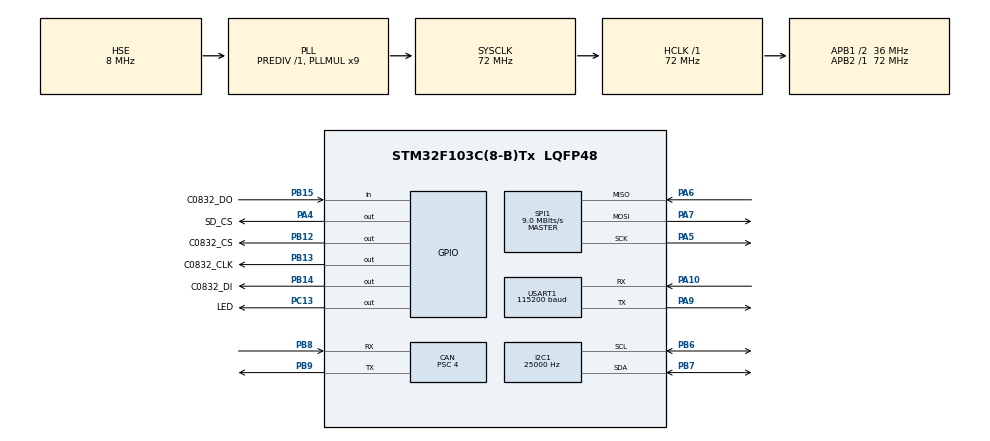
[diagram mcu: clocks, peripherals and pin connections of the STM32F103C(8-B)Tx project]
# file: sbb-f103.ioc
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CAN.BS1=CAN_BS1_6TQ
CAN.BS2=CAN_BS2_2TQ
CAN.CalculateBaudRate=1000000
CAN.CalculateTimeQuantum=111.11111111111111
CAN.Prescaler=4
CAN.SJW=CAN_SJW_1TQ
FREERTOS.INCLUDE_uxTaskGetStackHighWaterMark=1
FREERTOS.MEMORY_ALLOCATION=1
FREERTOS.Tasks01=defaultTask,0,128,StartDefaultTask,Default,NULL,Static,defaultTaskBuffer,defaultTaskControlBlock
FREERTOS.configCHECK_FOR_STACK_OVERFLOW=2
FREERTOS.copyHeapFile=0
I2C1.ClockSpeed=25000
Mcu.Family=STM32F1
Mcu.Name=STM32F103C(8-B)Tx
Mcu.Package=LQFP48
NVIC.PriorityGroup=NVIC_PRIORITYGROUP_4
NVIC.TIM3_IRQn=true\:15\:0\:false\:false\:true\:false\:false\:true\:true
NVIC.TimeBase=TIM3_IRQn
NVIC.TimeBaseIP=TIM3
PA10.Mode=Asynchronous
PA10.Signal=USART1_RX
PA13.Mode=Serial_Wire
PA13.Signal=SYS_JTMS-SWDIO
PA14.Mode=Serial_Wire
PA14.Signal=SYS_JTCK-SWCLK
PA4.GPIO_Label=SD_CS
PA4.Signal=GPIO_Output
PA5.Mode=Full_Duplex_Master
PA5.Signal=SPI1_SCK
PA6.Mode=Full_Duplex_Master
PA6.Signal=SPI1_MISO
PA7.Mode=Full_Duplex_Master
PA7.Signal=SPI1_MOSI
PA9.Mode=Asynchronous
PA9.Signal=USART1_TX
PB12.GPIO_Label=C0832_CS
PB12.PinState=GPIO_PIN_SET
PB12.Signal=GPIO_Output
PB13.GPIO_Label=C0832_CLK
PB13.PinState=GPIO_PIN_RESET
PB13.Signal=GPIO_Output
PB14.GPIO_Label=C0832_DI
PB14.PinState=GPIO_PIN_RESET
PB14.Signal=GPIO_Output
PB15.GPIO_Label=C0832_DO
PB15.GPIO_PuPd=GPIO_NOPULL
PB15.Signal=GPIO_Input
PB6.Mode=I2C
PB6.Signal=I2C1_SCL
PB7.Mode=I2C
PB7.Signal=I2C1_SDA
PB8.Mode=CAN_Activate
PB8.Signal=CAN_RX
PB9.Mode=CAN_Activate
PB9.Signal=CAN_TX
PC13-TAMPER-RTC.GPIO_Label=LED
PC13-TAMPER-RTC.PinState=GPIO_PIN_SET
PC13-TAMPER-RTC.Signal=GPIO_Output
PD0-OSC_IN.Mode=HSE-External-Oscillator
PD0-OSC_IN.Signal=RCC_OSC_IN
PD1-OSC_OUT.Mode=HSE-External-Oscillator
PD1-OSC_OUT.Signal=RCC_OSC_OUT
ProjectManager.HeapSize=0x200
ProjectManager.StackSize=0x400
ProjectManager.TargetToolchain=Makefile
RCC.AHBFreq_Value=72000000
RCC.APB1CLKDivider=RCC_HCLK_DIV2
RCC.APB1Freq_Value=36000000
RCC.APB1TimFreq_Value=72000000
RCC.APB2Freq_Value=72000000
RCC.APB2TimFreq_Value=72000000
RCC.HCLKFreq_Value=72000000
RCC.PLLMUL=RCC_PLL_MUL9
RCC.PLLSourceVirtual=RCC_PLLSOURCE_HSE
RCC.SYSCLKFreq_VALUE=72000000
RCC.SYSCLKSource=RCC_SYSCLKSOURCE_PLLCLK
RCC.USBFreq_Value=72000000
SPI1.BaudRatePrescaler=SPI_BAUDRATEPRESCALER_8
SPI1.CalculateBaudRate=9.0 MBits/s
SPI1.Direction=SPI_DIRECTION_2LINES
SPI1.Mode=SPI_MODE_MASTER
SPI1.VirtualType=VM_MASTER
USART1.BaudRate=115200
USART1.Mode=MODE_TX_RX
USART1.Parity=PARITY_NONE
USART1.StopBits=STOPBITS_1
USART1.VirtualMode=VM_ASYNC
USART1.WordLength=WORDLENGTH_8B
VP_FREERTOS_VS_CMSIS_V1.Mode=CMSIS_V1
VP_SYS_VS_tim3.Mode=TIM3
board=custom

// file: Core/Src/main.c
/* USER CODE BEGIN Header */
/**
  ******************************************************************************
  * @file           : main.c
  * @brief          : Main program body
  ******************************************************************************
  * @attention
  *
  * Copyright (c) 2026 STMicroelectronics.
  * All rights reserved.
  *
  * This software is licensed under terms that can be found in the LICENSE file
  * in the root directory of this software component.
  * If no LICENSE file comes with this software, it is provided AS-IS.
  *
  ******************************************************************************
  */
/* USER CODE END Header */
#include "main.h"
#include "cmsis_os.h"

/* USER CODE BEGIN Includes */
#include "app_main.h"      /* 应用层入口（App/app/app_main.c）*/
/* USER CODE END Includes */

CAN_HandleTypeDef hcan;

I2C_HandleTypeDef hi2c1;

SPI_HandleTypeDef hspi1;

UART_HandleTypeDef huart1;

osThreadId defaultTaskHandle;
uint32_t defaultTaskBuffer[ 128 ];
osStaticThreadDef_t defaultTaskControlBlock;

void SystemClock_Config(void);
static void MX_GPIO_Init(void);
static void MX_CAN_Init(void);
static void MX_I2C1_Init(void);
static void MX_SPI1_Init(void);
static void MX_USART1_UART_Init(void);
void StartDefaultTask(void const * argument);

int main(void)
{

  /* MCU Configuration--------------------------------------------------------*/

  /* Reset of all peripherals, Initializes the Flash interface and the Systick. */
  HAL_Init();

  /* Configure the system clock */
  SystemClock_Config();

  /* Initialize all configured peripherals */
  MX_GPIO_Init();
  MX_CAN_Init();
  MX_I2C1_Init();
  MX_SPI1_Init();
  MX_USART1_UART_Init();

  /* Create the thread(s) */
  /* definition and creation of defaultTask */
  osThreadStaticDef(defaultTask, StartDefaultTask, osPriorityNormal, 0, 128, defaultTaskBuffer, &defaultTaskControlBlock);
  defaultTaskHandle = osThreadCreate(osThread(defaultTask), NULL);

  /* USER CODE BEGIN RTOS_THREADS */
  /* 建应用任务（全静态分配，实现见 App/app/app_main.c）*/
  app_start();
  /* USER CODE END RTOS_THREADS */

  /* Start scheduler */
  osKernelStart();

  /* We should never get here as control is now taken by the scheduler */

  /* Infinite loop */
  while (1)
  {

  }
}

void SystemClock_Config(void)
{
  RCC_OscInitTypeDef RCC_OscInitStruct = {0};
  RCC_ClkInitTypeDef RCC_ClkInitStruct = {0};

  /** Initializes the RCC Oscillators according to the specified parameters
  * in the RCC_OscInitTypeDef structure.
  */
  RCC_OscInitStruct.OscillatorType = RCC_OSCILLATORTYPE_HSE;
  /* ★ [AI-TEMP-FIX] 由 RCC_HSE_BYPASS 改为 RCC_HSE_ON。
   *   蓝 pill 板载 8 MHz **无源晶振**，而原 .ioc 把 HSE 写成了
   *   "HSE-External-Clock-Source"（= bypass，期待外部时钟信号）→ HSERDY 永不置位
   *   → HAL_RCC_OscConfig 返回错误 → Error_Handler() 死循环，应用从未启动
   *   （真机证据：RCC_CR=0x00054783 即 HSEBYP=1/HSERDY=0，RCC_CFGR=0，xTickCount=0）。
   *   .ioc 已同步改为 HSE-External-Oscillator；**你在 CubeMX 里重新 GENERATE CODE
   *   后本行会被正确覆盖，届时可删除此注释**。留档见 docs/CUBEMX-TODO.md A0。 */
  RCC_OscInitStruct.HSEState = RCC_HSE_ON;
  RCC_OscInitStruct.HSEPredivValue = RCC_HSE_PREDIV_DIV1;
  RCC_OscInitStruct.HSIState = RCC_HSI_ON;
  RCC_OscInitStruct.PLL.PLLState = RCC_PLL_ON;
  RCC_OscInitStruct.PLL.PLLSource = RCC_PLLSOURCE_HSE;
  RCC_OscInitStruct.PLL.PLLMUL = RCC_PLL_MUL9;
  if (HAL_RCC_OscConfig(&RCC_OscInitStruct) != HAL_OK)
  {
    Error_Handler();
  }

  /** Initializes the CPU, AHB and APB buses clocks
  */
  RCC_ClkInitStruct.ClockType = RCC_CLOCKTYPE_HCLK|RCC_CLOCKTYPE_SYSCLK
                              |RCC_CLOCKTYPE_PCLK1|RCC_CLOCKTYPE_PCLK2;
  RCC_ClkInitStruct.SYSCLKSource = RCC_SYSCLKSOURCE_PLLCLK;
  RCC_ClkInitStruct.AHBCLKDivider = RCC_SYSCLK_DIV1;
  RCC_ClkInitStruct.APB1CLKDivider = RCC_HCLK_DIV2;
  RCC_ClkInitStruct.APB2CLKDivider = RCC_HCLK_DIV1;

  if (HAL_RCC_ClockConfig(&RCC_ClkInitStruct, FLASH_LATENCY_2) != HAL_OK)
  {
    Error_Handler();
  }
}

static void MX_CAN_Init(void)
{

  hcan.Instance = CAN1;
  hcan.Init.Prescaler = 4;
  hcan.Init.Mode = CAN_MODE_NORMAL;
  hcan.Init.SyncJumpWidth = CAN_SJW_1TQ;
  hcan.Init.TimeSeg1 = CAN_BS1_6TQ;
  hcan.Init.TimeSeg2 = CAN_BS2_2TQ;
  hcan.Init.TimeTriggeredMode = DISABLE;
  hcan.Init.AutoBusOff = DISABLE;
  hcan.Init.AutoWakeUp = DISABLE;
  hcan.Init.AutoRetransmission = DISABLE;
  hcan.Init.ReceiveFifoLocked = DISABLE;
  hcan.Init.TransmitFifoPriority = DISABLE;
  if (HAL_CAN_Init(&hcan) != HAL_OK)
  {
    Error_Handler();
  }

}

static void MX_I2C1_Init(void)
{

  hi2c1.Instance = I2C1;
  /* ★ 25kHz 而不是 50kHz/100kHz —— 真机实测结论，别轻易调高：
   *   本板 OLED 走线为长杜邦线，总线上升沿 t_r 实测约 1.3~2.1µs（模块自带约 10kΩ 上拉偏弱）。
   *   在 50kHz（周期 20µs）下外设会误采样 SCL，出现"面板半混乱 → 持续时钟拉伸"，
   *   单个 129 字节事务从理论 23ms 恶化到 330ms（刷屏 5.3s，实测）。
   *   25kHz 下实测单次刷屏 482ms（理论 372ms，1.3 倍，可接受）。
   *   根治办法是硬件：SCL/SDA 各并 4.7kΩ 到 3V3，之后才谈提速。
   *   ⚠ 改回高速度前，必须先复核 bsp_i2c.c 里的 BSP_I2C_TIMEOUT_MS 余量。 */
  hi2c1.Init.ClockSpeed = 25000;
  hi2c1.Init.DutyCycle = I2C_DUTYCYCLE_2;
  hi2c1.Init.OwnAddress1 = 0;
  hi2c1.Init.AddressingMode = I2C_ADDRESSINGMODE_7BIT;
  hi2c1.Init.DualAddressMode = I2C_DUALADDRESS_DISABLE;
  hi2c1.Init.OwnAddress2 = 0;
  hi2c1.Init.GeneralCallMode = I2C_GENERALCALL_DISABLE;
  hi2c1.Init.NoStretchMode = I2C_NOSTRETCH_DISABLE;
  if (HAL_I2C_Init(&hi2c1) != HAL_OK)
  {
    Error_Handler();
  }

}

static void MX_SPI1_Init(void)
{

  /* SPI1 parameter configuration*/
  hspi1.Instance = SPI1;
  hspi1.Init.Mode = SPI_MODE_MASTER;
  hspi1.Init.Direction = SPI_DIRECTION_2LINES;
  hspi1.Init.DataSize = SPI_DATASIZE_8BIT;
  hspi1.Init.CLKPolarity = SPI_POLARITY_LOW;
  hspi1.Init.CLKPhase = SPI_PHASE_1EDGE;
  hspi1.Init.NSS = SPI_NSS_SOFT;
  hspi1.Init.BaudRatePrescaler = SPI_BAUDRATEPRESCALER_8;
  hspi1.Init.FirstBit = SPI_FIRSTBIT_MSB;
  hspi1.Init.TIMode = SPI_TIMODE_DISABLE;
  hspi1.Init.CRCCalculation = SPI_CRCCALCULATION_DISABLE;
  hspi1.Init.CRCPolynomial = 10;
  if (HAL_SPI_Init(&hspi1) != HAL_OK)
  {
    Error_Handler();
  }

}

static void MX_USART1_UART_Init(void)
{

  huart1.Instance = USART1;
  huart1.Init.BaudRate = 115200;
  huart1.Init.WordLength = UART_WORDLENGTH_8B;
  huart1.Init.StopBits = UART_STOPBITS_1;
  huart1.Init.Parity = UART_PARITY_NONE;
  huart1.Init.Mode = UART_MODE_TX_RX;
  huart1.Init.HwFlowCtl = UART_HWCONTROL_NONE;
  huart1.Init.OverSampling = UART_OVERSAMPLING_16;
  if (HAL_UART_Init(&huart1) != HAL_OK)
  {
    Error_Handler();
  }

}

static void MX_GPIO_Init(void)
{
  GPIO_InitTypeDef GPIO_InitStruct = {0};

  /* GPIO Ports Clock Enable */
  __HAL_RCC_GPIOC_CLK_ENABLE();
  __HAL_RCC_GPIOD_CLK_ENABLE();
  __HAL_RCC_GPIOA_CLK_ENABLE();
  __HAL_RCC_GPIOB_CLK_ENABLE();

  /*Configure GPIO pin Output Level */
  HAL_GPIO_WritePin(LED_GPIO_Port, LED_Pin, GPIO_PIN_SET);

  /*Configure GPIO pin Output Level */
  HAL_GPIO_WritePin(SD_CS_GPIO_Port, SD_CS_Pin, GPIO_PIN_RESET);

  /*Configure GPIO pin Output Level */
  HAL_GPIO_WritePin(C0832_CS_GPIO_Port, C0832_CS_Pin, GPIO_PIN_SET);

  /*Configure GPIO pin Output Level */
  HAL_GPIO_WritePin(GPIOB, C0832_CLK_Pin|C0832_DI_Pin, GPIO_PIN_RESET);

  /*Configure GPIO pin : LED_Pin */
  GPIO_InitStruct.Pin = LED_Pin;
  GPIO_InitStruct.Mode = GPIO_MODE_OUTPUT_PP;
  GPIO_InitStruct.Pull = GPIO_NOPULL;
  GPIO_InitStruct.Speed = GPIO_SPEED_FREQ_LOW;
  HAL_GPIO_Init(LED_GPIO_Port, &GPIO_InitStruct);

  /*Configure GPIO pins : PC14 PC15 */
  GPIO_InitStruct.Pin = GPIO_PIN_14|GPIO_PIN_15;
  GPIO_InitStruct.Mode = GPIO_MODE_ANALOG;
  HAL_GPIO_Init(GPIOC, &GPIO_InitStruct);

  /*Configure GPIO pins : PA0 PA1 PA2 PA3
                           PA8 PA11 PA12 PA15 */
  GPIO_InitStruct.Pin = GPIO_PIN_0|GPIO_PIN_1|GPIO_PIN_2|GPIO_PIN_3
                          |GPIO_PIN_8|GPIO_PIN_11|GPIO_PIN_12|GPIO_PIN_15;
  GPIO_InitStruct.Mode = GPIO_MODE_ANALOG;
  HAL_GPIO_Init(GPIOA, &GPIO_InitStruct);

  /*Configure GPIO pin : SD_CS_Pin */
  GPIO_InitStruct.Pin = SD_CS_Pin;
  GPIO_InitStruct.Mode = GPIO_MODE_OUTPUT_PP;
  GPIO_InitStruct.Pull = GPIO_NOPULL;
  GPIO_InitStruct.Speed = GPIO_SPEED_FREQ_LOW;
  HAL_GPIO_Init(SD_CS_GPIO_Port, &GPIO_InitStruct);

  /*Configure GPIO pins : PB0 PB1 PB2 PB10
                           PB11 PB3 PB4 PB5 */
  GPIO_InitStruct.Pin = GPIO_PIN_0|GPIO_PIN_1|GPIO_PIN_2|GPIO_PIN_10
                          |GPIO_PIN_11|GPIO_PIN_3|GPIO_PIN_4|GPIO_PIN_5;
  GPIO_InitStruct.Mode = GPIO_MODE_ANALOG;
  HAL_GPIO_Init(GPIOB, &GPIO_InitStruct);

  /*Configure GPIO pins : C0832_CS_Pin C0832_CLK_Pin C0832_DI_Pin */
  GPIO_InitStruct.Pin = C0832_CS_Pin|C0832_CLK_Pin|C0832_DI_Pin;
  GPIO_InitStruct.Mode = GPIO_MODE_OUTPUT_PP;
  GPIO_InitStruct.Pull = GPIO_NOPULL;
  GPIO_InitStruct.Speed = GPIO_SPEED_FREQ_LOW;
  HAL_GPIO_Init(GPIOB, &GPIO_InitStruct);

  /*Configure GPIO pin : C0832_DO_Pin */
  GPIO_InitStruct.Pin = C0832_DO_Pin;
  GPIO_InitStruct.Mode = GPIO_MODE_INPUT;
  GPIO_InitStruct.Pull = GPIO_NOPULL;
  HAL_GPIO_Init(C0832_DO_GPIO_Port, &GPIO_InitStruct);

}

void StartDefaultTask(void const * argument)
{
  /* USER CODE BEGIN 5 */
  /* 应用监控任务：周期打印时钟/节拍/栈余量（实现见 App/app/app_main.c）*/
  app_monitor_task(argument);
  /* USER CODE END 5 */
}

void HAL_TIM_PeriodElapsedCallback(TIM_HandleTypeDef *htim)
{
  if (htim->Instance == TIM3)
  {
    HAL_IncTick();
  }
}

void Error_Handler(void)
{
  __disable_irq();
  while (1)
  {
  }
}
